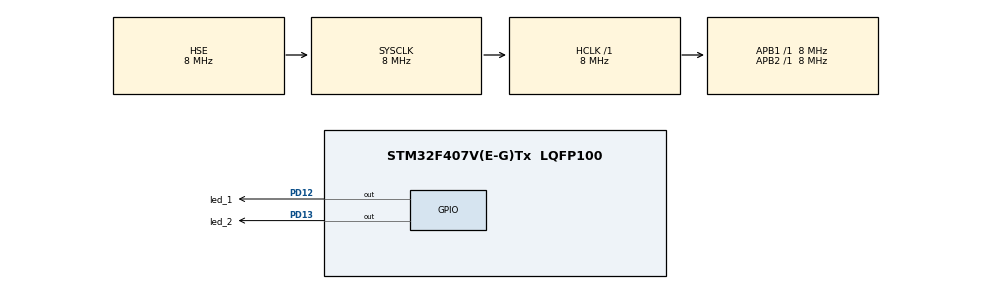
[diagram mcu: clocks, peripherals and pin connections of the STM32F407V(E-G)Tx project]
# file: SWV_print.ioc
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Mcu.Family=STM32F4
Mcu.Name=STM32F407V(E-G)Tx
Mcu.Package=LQFP100
NVIC.PriorityGroup=NVIC_PRIORITYGROUP_4
PA13.Mode=Trace_Asynchronous_SW
PA13.Signal=SYS_JTMS-SWDIO
PA14.Mode=Trace_Asynchronous_SW
PA14.Signal=SYS_JTCK-SWCLK
PB3.Mode=Trace_Asynchronous_SW
PB3.Signal=SYS_JTDO-SWO
PD12.GPIO_Label=led_1
PD12.Signal=GPIO_Output
PD13.GPIO_Label=led_2
PD13.Signal=GPIO_Output
PH0-OSC_IN.Mode=HSE-External-Oscillator
PH0-OSC_IN.Signal=RCC_OSC_IN
PH1-OSC_OUT.Mode=HSE-External-Oscillator
PH1-OSC_OUT.Signal=RCC_OSC_OUT
ProjectManager.HeapSize=0x200
ProjectManager.StackSize=0x400
ProjectManager.TargetToolchain=STM32CubeIDE
RCC.AHBFreq_Value=8000000
RCC.APB1Freq_Value=8000000
RCC.APB1TimFreq_Value=8000000
RCC.APB2Freq_Value=8000000
RCC.APB2TimFreq_Value=8000000
RCC.CortexFreq_Value=8000000
RCC.HCLKFreq_Value=8000000
RCC.HSE_VALUE=8000000
RCC.HSI_VALUE=16000000
RCC.LSE_VALUE=32768
RCC.SYSCLKFreq_VALUE=8000000
RCC.SYSCLKSource=RCC_SYSCLKSOURCE_HSE
RCC.VCOOutputFreq_Value=192000000
board=custom

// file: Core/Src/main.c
/* USER CODE BEGIN Header */
/**
  ******************************************************************************
  * @file           : main.c
  * @brief          : Main program body
  ******************************************************************************
  * @attention
  *
  * Copyright (c) 2022 STMicroelectronics.
  * All rights reserved.
  *
  * This software is licensed under terms that can be found in the LICENSE file
  * in the root directory of this software component.
  * If no LICENSE file comes with this software, it is provided AS-IS.
  *
  ******************************************************************************
  */
/* USER CODE END Header */
#include "main.h"

void SystemClock_Config(void);
static void MX_GPIO_Init(void);

/* USER CODE BEGIN 0 */
int _write(int file, char *ptr, int len)
{
  /* Implement your write code here, this is used by puts and printf for example */
  int i=0;
  for(i=0 ; i<len ; i++)
    ITM_SendChar((*ptr++));
  return len;
}
/* USER CODE END 0 */

int main(void)
{

  /* MCU Configuration--------------------------------------------------------*/

  /* Reset of all peripherals, Initializes the Flash interface and the Systick. */
  HAL_Init();

  /* Configure the system clock */
  SystemClock_Config();

  /* Initialize all configured peripherals */
  MX_GPIO_Init();
  /* USER CODE BEGIN 2 */
  printf("Ready %ld\n", HAL_GetTick());
  /* USER CODE END 2 */

  /* Infinite loop */
  while (1)
  {

    /* USER CODE BEGIN 3 */
	  HAL_GPIO_WritePin(led_1_GPIO_Port, led_1_Pin, GPIO_PIN_SET);
	  printf("Led 1 High %ld\n", HAL_GetTick());
	  HAL_Delay(1000);

	  HAL_GPIO_WritePin(led_1_GPIO_Port, led_1_Pin, GPIO_PIN_RESET);
	  printf("Led 1 Low  %ld\n", HAL_GetTick());
	  HAL_Delay(1000);

	  HAL_GPIO_WritePin(led_2_GPIO_Port, led_2_Pin, GPIO_PIN_SET);
	  printf("Led 2 High %ld\n", HAL_GetTick());
	  HAL_Delay(1000);

	  HAL_GPIO_WritePin(led_2_GPIO_Port, led_2_Pin, GPIO_PIN_RESET);
	  printf("Led 2 Low  %ld\n", HAL_GetTick());
	  HAL_Delay(1000);
  }
  /* USER CODE END 3 */
}

void SystemClock_Config(void)
{
  RCC_OscInitTypeDef RCC_OscInitStruct = {0};
  RCC_ClkInitTypeDef RCC_ClkInitStruct = {0};

  /** Configure the main internal regulator output voltage
  */
  __HAL_RCC_PWR_CLK_ENABLE();
  __HAL_PWR_VOLTAGESCALING_CONFIG(PWR_REGULATOR_VOLTAGE_SCALE1);

  /** Initializes the RCC Oscillators according to the specified parameters
  * in the RCC_OscInitTypeDef structure.
  */
  RCC_OscInitStruct.OscillatorType = RCC_OSCILLATORTYPE_HSE;
  RCC_OscInitStruct.HSEState = RCC_HSE_ON;
  RCC_OscInitStruct.PLL.PLLState = RCC_PLL_NONE;
  if (HAL_RCC_OscConfig(&RCC_OscInitStruct) != HAL_OK)
  {
    Error_Handler();
  }

  /** Initializes the CPU, AHB and APB buses clocks
  */
  RCC_ClkInitStruct.ClockType = RCC_CLOCKTYPE_HCLK|RCC_CLOCKTYPE_SYSCLK
                              |RCC_CLOCKTYPE_PCLK1|RCC_CLOCKTYPE_PCLK2;
  RCC_ClkInitStruct.SYSCLKSource = RCC_SYSCLKSOURCE_HSE;
  RCC_ClkInitStruct.AHBCLKDivider = RCC_SYSCLK_DIV1;
  RCC_ClkInitStruct.APB1CLKDivider = RCC_HCLK_DIV1;
  RCC_ClkInitStruct.APB2CLKDivider = RCC_HCLK_DIV1;

  if (HAL_RCC_ClockConfig(&RCC_ClkInitStruct, FLASH_LATENCY_0) != HAL_OK)
  {
    Error_Handler();
  }
}

static void MX_GPIO_Init(void)
{
  GPIO_InitTypeDef GPIO_InitStruct = {0};

  /* GPIO Ports Clock Enable */
  __HAL_RCC_GPIOH_CLK_ENABLE();
  __HAL_RCC_GPIOD_CLK_ENABLE();
  __HAL_RCC_GPIOA_CLK_ENABLE();
  __HAL_RCC_GPIOB_CLK_ENABLE();

  /*Configure GPIO pin Output Level */
  HAL_GPIO_WritePin(GPIOD, led_1_Pin|led_2_Pin, GPIO_PIN_RESET);

  /*Configure GPIO pins : led_1_Pin led_2_Pin */
  GPIO_InitStruct.Pin = led_1_Pin|led_2_Pin;
  GPIO_InitStruct.Mode = GPIO_MODE_OUTPUT_PP;
  GPIO_InitStruct.Pull = GPIO_NOPULL;
  GPIO_InitStruct.Speed = GPIO_SPEED_FREQ_LOW;
  HAL_GPIO_Init(GPIOD, &GPIO_InitStruct);

}

void Error_Handler(void)
{
  __disable_irq();
  while (1)
  {
  }
}
